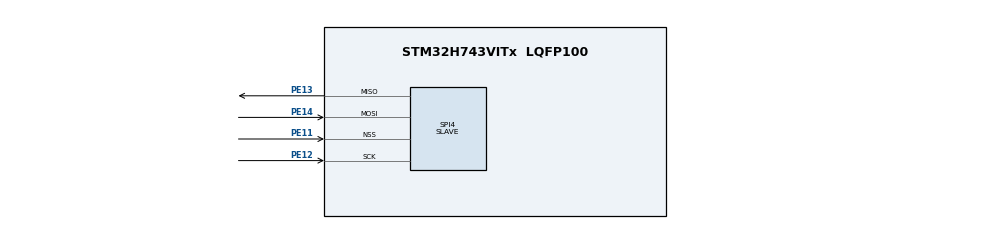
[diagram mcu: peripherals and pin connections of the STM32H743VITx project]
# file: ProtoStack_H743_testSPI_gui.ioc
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Dma.Request0=SPI4_RX
Dma.Request1=SPI4_TX
Dma.SPI4_RX.0.Direction=DMA_PERIPH_TO_MEMORY
Dma.SPI4_RX.0.EventEnable=DISABLE
Dma.SPI4_RX.0.FIFOMode=DMA_FIFOMODE_DISABLE
Dma.SPI4_RX.0.Instance=DMA1_Stream2
Dma.SPI4_RX.0.MemDataAlignment=DMA_MDATAALIGN_HALFWORD
Dma.SPI4_RX.0.MemInc=DMA_MINC_ENABLE
Dma.SPI4_RX.0.Mode=DMA_CIRCULAR
Dma.SPI4_RX.0.PeriphDataAlignment=DMA_PDATAALIGN_HALFWORD
Dma.SPI4_RX.0.PeriphInc=DMA_PINC_DISABLE
Dma.SPI4_RX.0.Polarity=HAL_DMAMUX_REQ_GEN_RISING
Dma.SPI4_RX.0.Priority=DMA_PRIORITY_LOW
Dma.SPI4_RX.0.RequestNumber=1
Dma.SPI4_RX.0.SignalID=NONE
Dma.SPI4_RX.0.SyncEnable=DISABLE
Dma.SPI4_RX.0.SyncPolarity=HAL_DMAMUX_SYNC_NO_EVENT
Dma.SPI4_RX.0.SyncRequestNumber=1
Dma.SPI4_RX.0.SyncSignalID=NONE
Dma.SPI4_TX.1.Direction=DMA_MEMORY_TO_PERIPH
Dma.SPI4_TX.1.EventEnable=DISABLE
Dma.SPI4_TX.1.FIFOMode=DMA_FIFOMODE_DISABLE
Dma.SPI4_TX.1.Instance=DMA1_Stream3
Dma.SPI4_TX.1.MemDataAlignment=DMA_MDATAALIGN_HALFWORD
Dma.SPI4_TX.1.MemInc=DMA_MINC_ENABLE
Dma.SPI4_TX.1.Mode=DMA_CIRCULAR
Dma.SPI4_TX.1.PeriphDataAlignment=DMA_PDATAALIGN_HALFWORD
Dma.SPI4_TX.1.PeriphInc=DMA_PINC_DISABLE
Dma.SPI4_TX.1.Polarity=HAL_DMAMUX_REQ_GEN_RISING
Dma.SPI4_TX.1.Priority=DMA_PRIORITY_LOW
Dma.SPI4_TX.1.RequestNumber=1
Dma.SPI4_TX.1.SignalID=NONE
Dma.SPI4_TX.1.SyncEnable=DISABLE
Dma.SPI4_TX.1.SyncPolarity=HAL_DMAMUX_SYNC_NO_EVENT
Dma.SPI4_TX.1.SyncRequestNumber=1
Dma.SPI4_TX.1.SyncSignalID=NONE
Mcu.Family=STM32H7
Mcu.Name=STM32H743VITx
Mcu.Package=LQFP100
NVIC.DMA1_Stream2_IRQn=true\:0\:0\:false\:false\:true\:false\:true\:true
NVIC.DMA1_Stream3_IRQn=true\:0\:0\:false\:false\:true\:false\:true\:true
NVIC.PriorityGroup=NVIC_PRIORITYGROUP_4
NVIC.SPI4_IRQn=true\:0\:0\:false\:false\:true\:false\:true\:true
PA13\ (JTMS/SWDIO).Mode=Serial_Wire
PA13\ (JTMS/SWDIO).Signal=DEBUG_JTMS-SWDIO
PA14\ (JTCK/SWCLK).Mode=Serial_Wire
PA14\ (JTCK/SWCLK).Signal=DEBUG_JTCK-SWCLK
PB13.GPIO_Speed=GPIO_SPEED_FREQ_VERY_HIGH
PB13.Signal=SPI2_SCK
PB14.GPIO_Speed=GPIO_SPEED_FREQ_VERY_HIGH
PB14.Signal=SPI2_MISO
PB15.GPIO_Speed=GPIO_SPEED_FREQ_VERY_HIGH
PB15.Signal=SPI2_MOSI
PE11.GPIO_Speed=GPIO_SPEED_FREQ_VERY_HIGH
PE11.Mode=NSS_Signal_Hard_Input
PE11.Signal=SPI4_NSS
PE12.GPIO_Speed=GPIO_SPEED_FREQ_VERY_HIGH
PE12.Mode=Full_Duplex_Slave
PE12.Signal=SPI4_SCK
PE13.GPIO_Speed=GPIO_SPEED_FREQ_VERY_HIGH
PE13.Mode=Full_Duplex_Slave
PE13.Signal=SPI4_MISO
PE14.GPIO_Speed=GPIO_SPEED_FREQ_VERY_HIGH
PE14.Mode=Full_Duplex_Slave
PE14.Signal=SPI4_MOSI
PH0-OSC_IN\ (PH0).Mode=HSE-External-Oscillator
PH0-OSC_IN\ (PH0).Signal=RCC_OSC_IN
PH1-OSC_OUT\ (PH1).Mode=HSE-External-Oscillator
PH1-OSC_OUT\ (PH1).Signal=RCC_OSC_OUT
ProjectManager.HeapSize=0x200
ProjectManager.StackSize=0x400
ProjectManager.TargetToolchain=STM32CubeIDE
RCC.ADCFreq_Value=96000000
RCC.APB1Freq_Value=120000000
RCC.APB2Freq_Value=120000000
RCC.APB3Freq_Value=120000000
RCC.APB4Freq_Value=120000000
RCC.CortexFreq_Value=480000000
RCC.D1PPRE=RCC_APB3_DIV2
RCC.D2PPRE1=RCC_APB1_DIV2
RCC.D2PPRE2=RCC_APB2_DIV2
RCC.D3PPRE=RCC_APB4_DIV2
RCC.DIVM1=4
RCC.DIVM2=8
RCC.DIVN1=160
RCC.DIVN2=64
RCC.DIVQ1=5
RCC.EnbaleCSS=true
RCC.HCLKFreq_Value=240000000
RCC.HPRE=RCC_HCLK_DIV2
RCC.HSE_VALUE=24000000
RCC.PLLSourceVirtual=RCC_PLLSOURCE_HSE
RCC.SYSCLKFreq_VALUE=480000000
RCC.SYSCLKSource=RCC_SYSCLKSOURCE_PLLCLK
RCC.Spi45ClockSelection=RCC_SPI45CLKSOURCE_PLL2
RCC.USBFreq_Value=192000000
SPI4.DataSize=SPI_DATASIZE_16BIT
SPI4.Direction=SPI_DIRECTION_2LINES
SPI4.Mode=SPI_MODE_SLAVE
SPI4.VirtualNSS=VM_NSSHARD
SPI4.VirtualType=VM_SLAVE
board=custom

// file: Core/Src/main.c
/* USER CODE BEGIN Header */
/**
  ******************************************************************************
  * @file           : main.c
  * @brief          : Main program body
  ******************************************************************************
  * @attention
  *
  * Copyright (c) 2023 STMicroelectronics.
  * All rights reserved.
  *
  * This software is licensed under terms that can be found in the LICENSE file
  * in the root directory of this software component.
  * If no LICENSE file comes with this software, it is provided AS-IS.
  *
  ******************************************************************************
  */
/* USER CODE END Header */
#include "main.h"
#include "dma.h"
#include "spi.h"
#include "gpio.h"

/* USER CODE BEGIN PV */
#define BUFSIZE 1024
uint16_t spiTxbuf[BUFSIZE];
uint16_t spiRxbuf[BUFSIZE];
/* USER CODE END PV */

void SystemClock_Config(void);

int main(void)
{

  /* MCU Configuration--------------------------------------------------------*/

  /* Reset of all peripherals, Initializes the Flash interface and the Systick. */
  HAL_Init();

  /* Configure the system clock */
  SystemClock_Config();

  /* Initialize all configured peripherals */
  MX_GPIO_Init();
  MX_DMA_Init();
  MX_SPI4_Init();
  /* USER CODE BEGIN 2 */
  for(int i = 0; i < BUFSIZE; i++) {
	  spiTxbuf[i] = BUFSIZE-i-1;
	  spiRxbuf[i] = 0;
  }
  HAL_SPI_TransmitReceive_DMA(&hspi4, spiTxbuf, spiRxbuf, BUFSIZE);
  /* USER CODE END 2 */

  /* Infinite loop */
  while (1)
  {

  }
}

void SystemClock_Config(void)
{
  RCC_OscInitTypeDef RCC_OscInitStruct = {0};
  RCC_ClkInitTypeDef RCC_ClkInitStruct = {0};

  /** Supply configuration update enable
  */
  HAL_PWREx_ConfigSupply(PWR_LDO_SUPPLY);

  /** Configure the main internal regulator output voltage
  */
  __HAL_PWR_VOLTAGESCALING_CONFIG(PWR_REGULATOR_VOLTAGE_SCALE1);

  while(!__HAL_PWR_GET_FLAG(PWR_FLAG_VOSRDY)) {}

  __HAL_RCC_SYSCFG_CLK_ENABLE();
  __HAL_PWR_VOLTAGESCALING_CONFIG(PWR_REGULATOR_VOLTAGE_SCALE0);

  while(!__HAL_PWR_GET_FLAG(PWR_FLAG_VOSRDY)) {}

  /** Macro to configure the PLL clock source
  */
  __HAL_RCC_PLL_PLLSOURCE_CONFIG(RCC_PLLSOURCE_HSE);

  /** Initializes the RCC Oscillators according to the specified parameters
  * in the RCC_OscInitTypeDef structure.
  */
  RCC_OscInitStruct.OscillatorType = RCC_OSCILLATORTYPE_HSE;
  RCC_OscInitStruct.HSEState = RCC_HSE_ON;
  RCC_OscInitStruct.PLL.PLLState = RCC_PLL_ON;
  RCC_OscInitStruct.PLL.PLLSource = RCC_PLLSOURCE_HSE;
  RCC_OscInitStruct.PLL.PLLM = 4;
  RCC_OscInitStruct.PLL.PLLN = 160;
  RCC_OscInitStruct.PLL.PLLP = 2;
  RCC_OscInitStruct.PLL.PLLQ = 5;
  RCC_OscInitStruct.PLL.PLLR = 2;
  RCC_OscInitStruct.PLL.PLLRGE = RCC_PLL1VCIRANGE_2;
  RCC_OscInitStruct.PLL.PLLVCOSEL = RCC_PLL1VCOWIDE;
  RCC_OscInitStruct.PLL.PLLFRACN = 0;
  if (HAL_RCC_OscConfig(&RCC_OscInitStruct) != HAL_OK)
  {
    Error_Handler();
  }

  /** Initializes the CPU, AHB and APB buses clocks
  */
  RCC_ClkInitStruct.ClockType = RCC_CLOCKTYPE_HCLK|RCC_CLOCKTYPE_SYSCLK
                              |RCC_CLOCKTYPE_PCLK1|RCC_CLOCKTYPE_PCLK2
                              |RCC_CLOCKTYPE_D3PCLK1|RCC_CLOCKTYPE_D1PCLK1;
  RCC_ClkInitStruct.SYSCLKSource = RCC_SYSCLKSOURCE_PLLCLK;
  RCC_ClkInitStruct.SYSCLKDivider = RCC_SYSCLK_DIV1;
  RCC_ClkInitStruct.AHBCLKDivider = RCC_HCLK_DIV2;
  RCC_ClkInitStruct.APB3CLKDivider = RCC_APB3_DIV2;
  RCC_ClkInitStruct.APB1CLKDivider = RCC_APB1_DIV2;
  RCC_ClkInitStruct.APB2CLKDivider = RCC_APB2_DIV2;
  RCC_ClkInitStruct.APB4CLKDivider = RCC_APB4_DIV2;

  if (HAL_RCC_ClockConfig(&RCC_ClkInitStruct, FLASH_LATENCY_4) != HAL_OK)
  {
    Error_Handler();
  }

  /** Enables the Clock Security System
  */
  HAL_RCC_EnableCSS();
}

/* USER CODE BEGIN 4 */

void HAL_SPI_RxTxCpltCallback(SPI_HandleTypeDef *hspi) {
	__NOP();
}

/* USER CODE END 4 */

void Error_Handler(void)
{
  __disable_irq();
  while (1)
  {
  }
}
